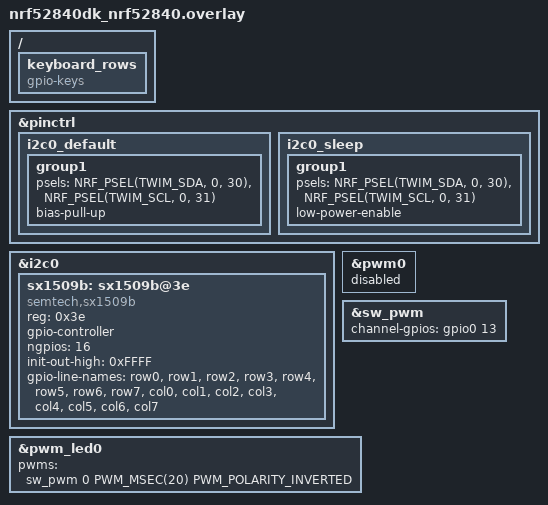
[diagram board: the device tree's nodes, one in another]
&pinctrl {
   i2c0_default: i2c0_default {
      group1 {
         psels = <NRF_PSEL(TWIM_SDA, 0, 30)>,
            <NRF_PSEL(TWIM_SCL, 0, 31)>;
            bias-pull-up;
      };
   };
   i2c0_sleep: i2c0_sleep {
      group1 {
         psels = <NRF_PSEL(TWIM_SDA, 0, 30)>,
            <NRF_PSEL(TWIM_SCL, 0, 31)>;
                 low-power-enable;
      };
   };
};

&i2c0 {

	sx1509b: sx1509b@3e {
		compatible = "semtech,sx1509b";
		reg = <0x3e>;
		gpio-controller;
		#gpio-cells = <2>;
		ngpios = <16>;
        init-out-high = <0xFFFF>;
        gpio-line-names = "row0", "row1", "row2", "row3", "row4", "row5", "row6", "row7", "col0", "col1", "col2", "col3", "col4", "col5", "col6", "col7";
	};
};

/ {
    keyboard_rows {
        compatible = "gpio-keys";

    };
};

&pwm0 {
    status = "disabled";
};

&sw_pwm {
    status = "okay";
    channel-gpios = <&gpio0 13 PWM_POLARITY_INVERTED>;
};

&pwm_led0 {
    pwms = <&sw_pwm 0 PWM_MSEC(20) PWM_POLARITY_INVERTED>;
};
